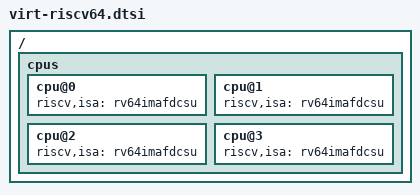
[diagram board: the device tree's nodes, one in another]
/*
 * Copyright (c) 2024 Antmicro <www.antmicro.com>
 *
 * SPDX-License-Identifier: Apache-2.0
 */

/dts-v1/;

#include <qemu/virt-riscv.dtsi>

/ {
	cpus {
		cpu@0 {
			riscv,isa = "rv64imafdcsu";
		};

		cpu@1 {
			riscv,isa = "rv64imafdcsu";
		};

		cpu@2 {
			riscv,isa = "rv64imafdcsu";
		};

		cpu@3 {
			riscv,isa = "rv64imafdcsu";
		};
	};
};
